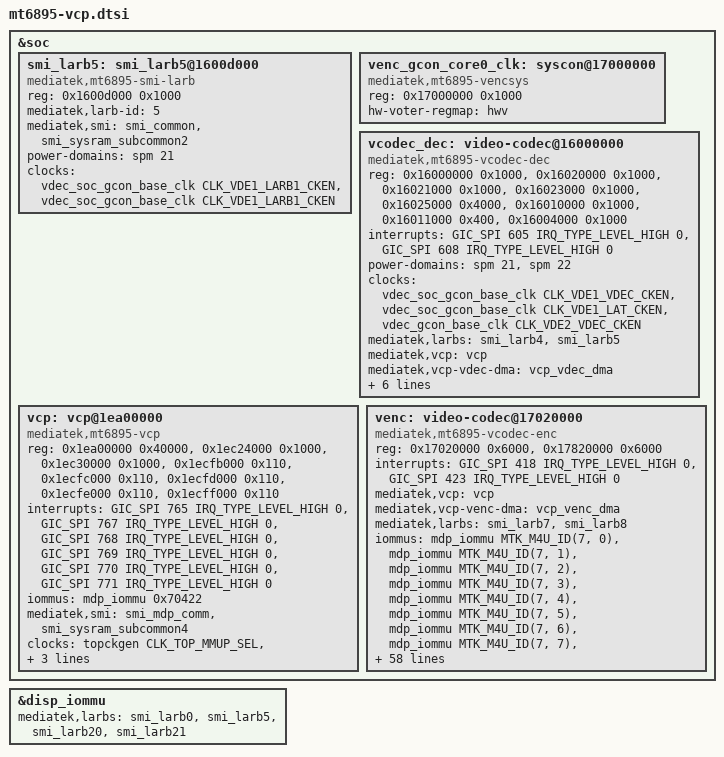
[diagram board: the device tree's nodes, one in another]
// SPDX-License-Identifier: (GPL-2.0 OR BSD-2-Clause)
/*
 * MT6895 VCP 编解码平台节点（从 xaga 分支的 mt6895.dtsi 抽出）。
 *
 * 单独成文件是为了不碰我们自己的 mt6895.dtsi：那里和 xaga 的基线差异很大，
 * 直接打 diff 会反复冲突（尤其 scp@1c700000 我们已经有自己的版本）。
 *
 * 有意剔除的部分（会动频率/电源域/内存布局，先不引入）：
 *   - MFG / disp0 / mminfra 的 OPP 调压表与 DVFSRC 相关改动
 *   - xaga 板级 reserved-memory 重排
 * 编解码节点里的 operating-points-v2 也一并去掉了，先验证能不能 probe。
 */

&soc {
		smi_larb5: smi_larb5@1600d000 {
			compatible = "mediatek,mt6895-smi-larb", "mediatek,smi-larb";
			reg = <0x1600d000 0x1000>;
			mediatek,larb-id = <5>;
			mediatek,smi = <&smi_common &smi_sysram_subcommon2>;
			power-domains = <&spm 21>;
			clocks = <&vdec_soc_gcon_base_clk CLK_VDE1_LARB1_CKEN>,
				 <&vdec_soc_gcon_base_clk CLK_VDE1_LARB1_CKEN>;
			clock-names = "apb", "smi";
		};

		venc_gcon_core0_clk: syscon@17000000 {
			compatible = "mediatek,mt6895-vencsys", "syscon";
			reg = <0x17000000 0x1000>;
			#clock-cells = <1>;
			hw-voter-regmap = <&hwv>;
		};

		vcodec_dec: video-codec@16000000 {
			compatible = "mediatek,mt6895-vcodec-dec";
			reg = <0x16000000 0x1000>, <0x16020000 0x1000>,
			      <0x16021000 0x1000>, <0x16023000 0x1000>,
			      <0x16025000 0x4000>, <0x16010000 0x1000>,
			      <0x16011000 0x400>, <0x16004000 0x1000>;
			reg-names = "base", "vld", "mc", "mv", "misc",
				    "lat-misc", "lat-vld", "racing";
			interrupts = <GIC_SPI 605 IRQ_TYPE_LEVEL_HIGH 0>,
				     <GIC_SPI 608 IRQ_TYPE_LEVEL_HIGH 0>;
			interrupt-names = "core", "lat";
			power-domains = <&spm 21>, <&spm 22>;
			clocks = <&vdec_soc_gcon_base_clk CLK_VDE1_VDEC_CKEN>,
				 <&vdec_soc_gcon_base_clk CLK_VDE1_LAT_CKEN>,
				 <&vdec_gcon_base_clk CLK_VDE2_VDEC_CKEN>;
			clock-names = "soc", "lat", "core";
			mediatek,larbs = <&smi_larb4 &smi_larb5>;
			mediatek,vcp = <&vcp>;
			mediatek,vcp-vdec-dma = <&vcp_vdec_dma>;
			mediatek,vdec-ube-dma = <&vdec_ube_dma>;
			iommus = <&mdp_iommu 0x80>, <&mdp_iommu 0x81>,
				 <&mdp_iommu 0x82>, <&mdp_iommu 0x83>,
				 <&mdp_iommu 0x84>, <&mdp_iommu 0x85>,
				 <&mdp_iommu 0x86>, <&mdp_iommu 0x88>,
				 <&mdp_iommu 0x89>, <&mdp_iommu 0x8a>;
		};

		vcp: vcp@1ea00000 {
			compatible = "mediatek,mt6895-vcp";
			reg = <0x1ea00000 0x40000>,
			      <0x1ec24000 0x1000>,
			      <0x1ec30000 0x1000>,
			      <0x1ecfb000 0x110>,
			      <0x1ecfc000 0x110>,
			      <0x1ecfd000 0x110>,
			      <0x1ecfe000 0x110>,
			      <0x1ecff000 0x110>;
			reg-names = "sram", "cfg", "core0",
				    "mbox0", "mbox1", "mbox2", "mbox3", "mbox4";
			interrupts = <GIC_SPI 765 IRQ_TYPE_LEVEL_HIGH 0>,
				     <GIC_SPI 767 IRQ_TYPE_LEVEL_HIGH 0>,
				     <GIC_SPI 768 IRQ_TYPE_LEVEL_HIGH 0>,
				     <GIC_SPI 769 IRQ_TYPE_LEVEL_HIGH 0>,
				     <GIC_SPI 770 IRQ_TYPE_LEVEL_HIGH 0>,
				     <GIC_SPI 771 IRQ_TYPE_LEVEL_HIGH 0>;
			interrupt-names = "wdt", "mbox0", "mbox1", "mbox2", "mbox3", "mbox4";
			/* table0, video domain7, pseudo-larb33, port2 */
			iommus = <&mdp_iommu 0x70422>;
			mediatek,smi = <&smi_mdp_comm &smi_sysram_subcommon4>;
			clocks = <&topckgen CLK_TOP_MMUP_SEL>,
				 <&topckgen CLK_TOP_MAINPLL_D3>,
				 <&topckgen CLK_TOP_TCK_26M_MX9>;
			clock-names = "mmup-sel", "mmup-clk", "mmup-26m";
			power-domains = <&spm 25>;
			/* VCP remains auto_boot=false; codec opens explicitly boot it. */
		};

		venc: video-codec@17020000 {
			compatible = "mediatek,mt6895-vcodec-enc";
			reg = <0x17020000 0x6000>,
			      <0x17820000 0x6000>;
			reg-names = "VENC_SYS", "VENC_C1_SYS";
			interrupts = <GIC_SPI 418 IRQ_TYPE_LEVEL_HIGH 0>,
				     <GIC_SPI 423 IRQ_TYPE_LEVEL_HIGH 0>;
			mediatek,vcp = <&vcp>;
			mediatek,vcp-venc-dma = <&vcp_venc_dma>;
			mediatek,larbs = <&smi_larb7 &smi_larb8>;
			/* Both cores use table0/domain0; port list follows vendor port-def. */
			iommus =
				 <&mdp_iommu MTK_M4U_ID(7, 0)>,
				 <&mdp_iommu MTK_M4U_ID(7, 1)>,
				 <&mdp_iommu MTK_M4U_ID(7, 2)>,
				 <&mdp_iommu MTK_M4U_ID(7, 3)>,
				 <&mdp_iommu MTK_M4U_ID(7, 4)>,
				 <&mdp_iommu MTK_M4U_ID(7, 5)>,
				 <&mdp_iommu MTK_M4U_ID(7, 6)>,
				 <&mdp_iommu MTK_M4U_ID(7, 7)>,
				 <&mdp_iommu MTK_M4U_ID(7, 8)>,
				 <&mdp_iommu MTK_M4U_ID(7, 9)>,
				 <&mdp_iommu MTK_M4U_ID(7, 10)>,
				 <&mdp_iommu MTK_M4U_ID(7, 11)>,
				 <&mdp_iommu MTK_M4U_ID(7, 12)>,
				 <&mdp_iommu MTK_M4U_ID(7, 13)>,
				 <&mdp_iommu MTK_M4U_ID(7, 14)>,
				 <&mdp_iommu MTK_M4U_ID(7, 15)>,
				 <&mdp_iommu MTK_M4U_ID(7, 16)>,
				 <&mdp_iommu MTK_M4U_ID(7, 17)>,
				 <&mdp_iommu MTK_M4U_ID(7, 18)>,
				 <&mdp_iommu MTK_M4U_ID(7, 19)>,
				 <&mdp_iommu MTK_M4U_ID(7, 20)>,
				 <&mdp_iommu MTK_M4U_ID(7, 21)>,
				 <&mdp_iommu MTK_M4U_ID(7, 22)>,
				 <&mdp_iommu MTK_M4U_ID(7, 23)>,
				 <&mdp_iommu MTK_M4U_ID(7, 24)>,
				 <&mdp_iommu MTK_M4U_ID(7, 25)>,
				 <&mdp_iommu MTK_M4U_ID(7, 26)>,
				 <&mdp_iommu MTK_M4U_ID(7, 27)>,
				 <&mdp_iommu MTK_M4U_ID(7, 28)>,
				 <&mdp_iommu MTK_M4U_ID(7, 29)>,
				 <&mdp_iommu MTK_M4U_ID(7, 30)>,
				 <&mdp_iommu MTK_M4U_ID(8, 0)>,
				 <&mdp_iommu MTK_M4U_ID(8, 1)>,
				 <&mdp_iommu MTK_M4U_ID(8, 2)>,
				 <&mdp_iommu MTK_M4U_ID(8, 3)>,
				 <&mdp_iommu MTK_M4U_ID(8, 4)>,
				 <&mdp_iommu MTK_M4U_ID(8, 5)>,
				 <&mdp_iommu MTK_M4U_ID(8, 6)>,
				 <&mdp_iommu MTK_M4U_ID(8, 7)>,
				 <&mdp_iommu MTK_M4U_ID(8, 8)>,
				 <&mdp_iommu MTK_M4U_ID(8, 9)>,
				 <&mdp_iommu MTK_M4U_ID(8, 10)>,
				 <&mdp_iommu MTK_M4U_ID(8, 11)>,
				 <&mdp_iommu MTK_M4U_ID(8, 12)>,
				 <&mdp_iommu MTK_M4U_ID(8, 13)>,
				 <&mdp_iommu MTK_M4U_ID(8, 14)>,
				 <&mdp_iommu MTK_M4U_ID(8, 15)>,
				 <&mdp_iommu MTK_M4U_ID(8, 16)>,
				 <&mdp_iommu MTK_M4U_ID(8, 17)>,
				 <&mdp_iommu MTK_M4U_ID(8, 18)>,
				 <&mdp_iommu MTK_M4U_ID(8, 19)>,
				 <&mdp_iommu MTK_M4U_ID(8, 20)>,
				 <&mdp_iommu MTK_M4U_ID(8, 21)>,
				 <&mdp_iommu MTK_M4U_ID(8, 22)>,
				 <&mdp_iommu MTK_M4U_ID(8, 23)>,
				 <&mdp_iommu MTK_M4U_ID(8, 24)>,
				 <&mdp_iommu MTK_M4U_ID(8, 25)>,
				 <&mdp_iommu MTK_M4U_ID(8, 26)>,
				 <&mdp_iommu MTK_M4U_ID(8, 27)>,
				 <&mdp_iommu MTK_M4U_ID(8, 28)>,
				 <&mdp_iommu MTK_M4U_ID(8, 29)>,
				 <&mdp_iommu MTK_M4U_ID(8, 30)>;
			clocks = <&venc_gcon_core0_clk CLK_VEN1_CKE1_VENC>,
				 <&venc_gcon_core1_clk CLK_VEN2_CKE1_VENC>;
			clock-names = "venc_sel", "venc_c1_sel";
			power-domains = <&spm 23>, <&spm 24>;
		};

};

&disp_iommu {
	mediatek,larbs = <&smi_larb0 &smi_larb5 &smi_larb20 &smi_larb21>;
};
